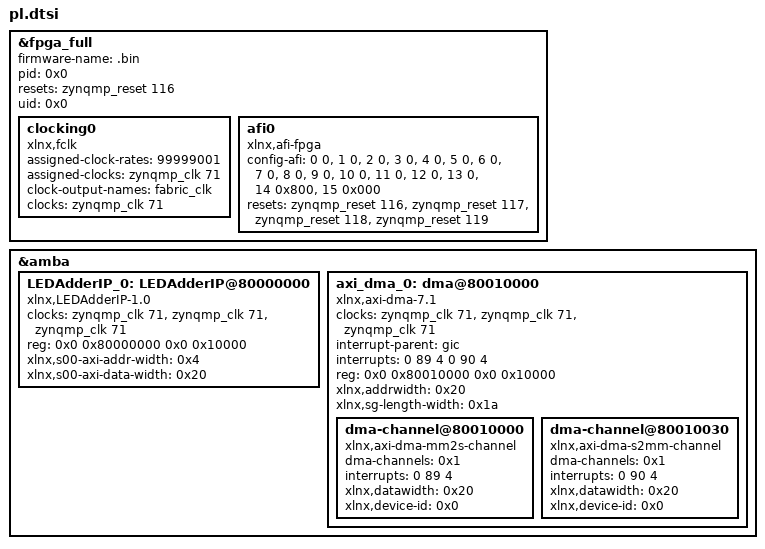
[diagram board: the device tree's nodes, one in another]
/*
 * CAUTION: This file is automatically generated by Xilinx.
 * Version: XSCT 2024.1
 * Today is: Sat Aug 16 20:58:08 2025
 */


/dts-v1/;
/plugin/;
&fpga_full {
	firmware-name = ".bin";
	pid = <0x0>;
	resets = <&zynqmp_reset 116>;
	uid = <0x0>;
	clocking0: clocking0 {
		#clock-cells = <0>;
		assigned-clock-rates = <99999001>;
		assigned-clocks = <&zynqmp_clk 71>;
		clock-output-names = "fabric_clk";
		clocks = <&zynqmp_clk 71>;
		compatible = "xlnx,fclk";
	};
	afi0: afi0 {
		compatible = "xlnx,afi-fpga";
		config-afi = < 0 0>, <1 0>, <2 0>, <3 0>, <4 0>, <5 0>, <6 0>, <7 0>, <8 0>, <9 0>, <10 0>, <11 0>, <12 0>, <13 0>, <14 0x800>, <15 0x000>;
		resets = <&zynqmp_reset 116>, <&zynqmp_reset 117>, <&zynqmp_reset 118>, <&zynqmp_reset 119>;
	};
};
&amba {
	#address-cells = <2>;
	#size-cells = <2>;
	LEDAdderIP_0: LEDAdderIP@80000000 {
		/* This is a place holder node for a custom IP, user may need to update the entries */
		clock-names = "m00_axis_aclk", "s00_axi_aclk", "s00_axis_aclk";
		clocks = <&zynqmp_clk 71>, <&zynqmp_clk 71>, <&zynqmp_clk 71>;
		compatible = "xlnx,LEDAdderIP-1.0";
		reg = <0x0 0x80000000 0x0 0x10000>;
		xlnx,s00-axi-addr-width = <0x4>;
		xlnx,s00-axi-data-width = <0x20>;
	};
	axi_dma_0: dma@80010000 {
		#dma-cells = <1>;
		clock-names = "m_axi_mm2s_aclk", "m_axi_s2mm_aclk", "s_axi_lite_aclk";
		clocks = <&zynqmp_clk 71>, <&zynqmp_clk 71>, <&zynqmp_clk 71>;
		compatible = "xlnx,axi-dma-7.1", "xlnx,axi-dma-1.00.a";
		interrupt-names = "mm2s_introut", "s2mm_introut";
		interrupt-parent = <&gic>;
		interrupts = <0 89 4 0 90 4>;
		reg = <0x0 0x80010000 0x0 0x10000>;
		xlnx,addrwidth = <0x20>;
		xlnx,sg-length-width = <0x1a>;
		dma-channel@80010000 {
			compatible = "xlnx,axi-dma-mm2s-channel";
			dma-channels = <0x1>;
			interrupts = <0 89 4>;
			xlnx,datawidth = <0x20>;
			xlnx,device-id = <0x0>;
		};
		dma-channel@80010030 {
			compatible = "xlnx,axi-dma-s2mm-channel";
			dma-channels = <0x1>;
			interrupts = <0 90 4>;
			xlnx,datawidth = <0x20>;
			xlnx,device-id = <0x0>;
		};
	};
};
